LIN_description_file;
LIN_protocol_version = "2.0";
LIN_language_version = "2.0";
LIN_speed = 19.2 kbps;

Nodes {
  Master: commander, 10 ms, 0.9 ms;
  Slaves: eval_0, eval_1, eval_2;
}

Signals {
  eval_0_rgb_r: 8, 0, commander, eval_0;
  eval_0_rgb_g: 8, 0, commander, eval_0;
  eval_0_rgb_b: 8, 0, commander, eval_0;
  eval_0_led0: 1, 0, commander, eval_0;
  eval_0_led1: 1, 0, commander, eval_0;
  eval_0_led2: 1, 0, commander, eval_0;
  eval_0_led3: 1, 0, commander, eval_0;
  eval_0_photores_mV: 16, 0, eval_0, commander;
  eval_0_temp_C: 16, 65536, eval_0, commander;

  eval_1_rgb_r: 8, 0, commander, eval_1;
  eval_1_rgb_g: 8, 0, commander, eval_1;
  eval_1_rgb_b: 8, 0, commander, eval_1;
  eval_1_led0: 1, 0, commander, eval_1;
  eval_1_led1: 1, 0, commander, eval_1;
  eval_1_led2: 1, 0, commander, eval_1;
  eval_1_led3: 1, 0, commander, eval_1;
  eval_1_photores_mV: 16, 0, eval_1, commander;
  eval_1_temp_C: 16, 65536, eval_0, commander;

  eval_2_rgb_r: 8, 0, commander, eval_2;
  eval_2_rgb_g: 8, 0, commander, eval_2;
  eval_2_rgb_b: 8, 0, commander, eval_2;
  eval_2_led0: 1, 0, commander, eval_2;
  eval_2_led1: 1, 0, commander, eval_2;
  eval_2_led2: 1, 0, commander, eval_2;
  eval_2_led3: 1, 0, commander, eval_2;
  eval_2_photores_mV: 16, 0, eval_2, commander;
  eval_2_temp_C: 16, 65536, eval_0, commander;
}

Frames {
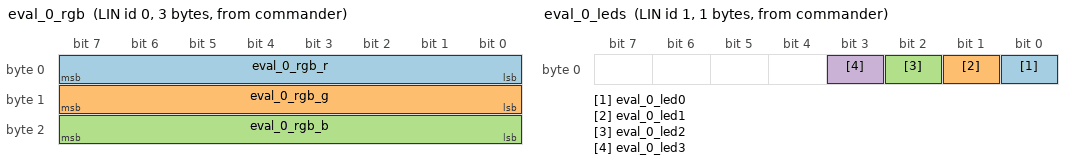
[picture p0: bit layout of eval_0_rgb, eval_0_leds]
  eval_0_rgb: 0, commander, 3 {
    eval_0_rgb_r, 0;
    eval_0_rgb_g, 8;
    eval_0_rgb_b, 16;
  }

  eval_0_leds: 1, commander, 1 {
    eval_0_led0, 0;
    eval_0_led1, 1;
    eval_0_led2, 2;
    eval_0_led3, 3;
  }

  eval_0_photores: 2, eval_0, 2 {
    eval_0_photores_mV, 0;
  }

  eval_0_temp: 3, eval_0, 2 {
    eval_0_temp_C, 0;
  }

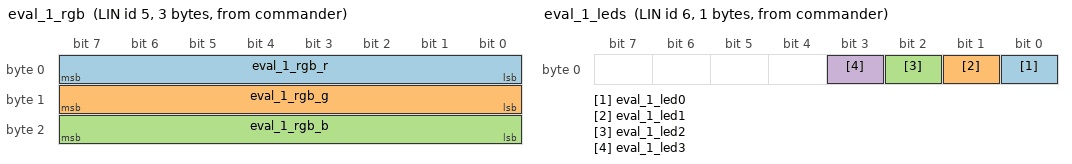
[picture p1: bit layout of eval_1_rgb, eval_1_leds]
  eval_1_rgb: 5, commander, 3 {
    eval_1_rgb_r, 0;
    eval_1_rgb_g, 8;
    eval_1_rgb_b, 16;
  }

  eval_1_leds: 6, commander, 1 {
    eval_1_led0, 0;
    eval_1_led1, 1;
    eval_1_led2, 2;
    eval_1_led3, 3;
  }

  eval_1_photores: 7, eval_1, 2 {
    eval_1_photores_mV, 0;
  }

  eval_1_temp: 8, eval_1, 2 {
    eval_1_temp_C, 0;
  }

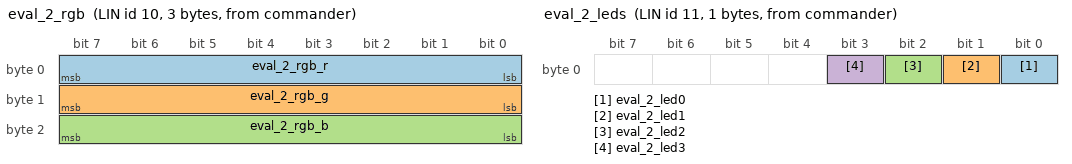
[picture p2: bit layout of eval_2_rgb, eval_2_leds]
  eval_2_rgb: 10, commander, 3 {
    eval_2_rgb_r, 0;
    eval_2_rgb_g, 8;
    eval_2_rgb_b, 16;
  }

  eval_2_leds: 11, commander, 1 {
    eval_2_led0, 0;
    eval_2_led1, 1;
    eval_2_led2, 2;
    eval_2_led3, 3;
  }

  eval_2_photores: 12, eval_2, 2 {
    eval_2_photores_mV, 0;
  }

  eval_2_temp: 13, eval_2, 2 {
    eval_2_temp_C, 0;
  }
}

Signal_representation {
  Enc_temp: eval_0_temp_C, eval_1_temp_C, eval_2_temp_C;
}

Signal_encoding_types {
  Enc_temp {
    physical_value, 0, 65534, 0.0625, 0, "°C";
    logical_value, 65535, "No measurement";
  }
}

Node_attributes {
  eval_0 {
    LIN_protocol = 2.0;
    configured_NAD = 0;
  }
  eval_1 {
    LIN_protocol = 2.0;
    configured_NAD = 0;
  }
  eval_2 {
    LIN_protocol = 2.0;
    configured_NAD = 0;
  }
}
